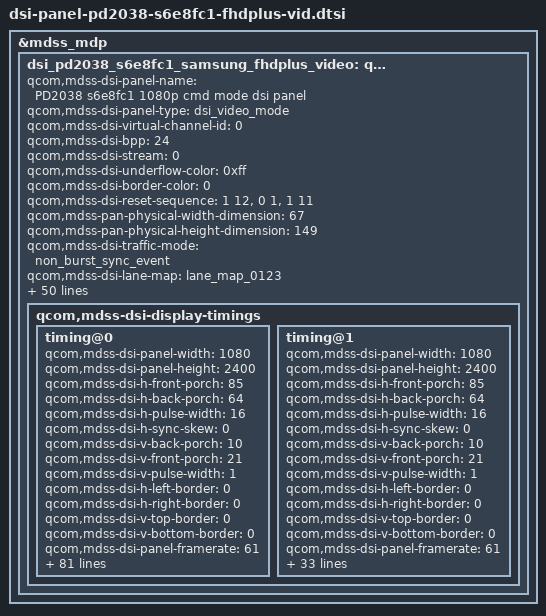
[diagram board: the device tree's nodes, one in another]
/* Copyright (c) 2019, The Linux Foundation. All rights reserved.
 *
 * This program is free software; you can redistribute it and/or modify
 * it under the terms of the GNU General Public License version 2 and
 * only version 2 as published by the Free Software Foundation.
 *
 * This program is distributed in the hope that it will be useful,
 * but WITHOUT ANY WARRANTY; without even the implied warranty of
 * MERCHANTABILITY or FITNESS FOR A PARTICULAR PURPOSE.  See the
 * GNU General Public License for more details.
 */

&mdss_mdp {
	dsi_pd2038_s6e8fc1_samsung_fhdplus_video: qcom,PD2038_mdss_dsi_s6e8fc1_fhdplus_cmd {
		qcom,mdss-dsi-panel-name = "PD2038 s6e8fc1 1080p cmd mode dsi panel";
		qcom,mdss-dsi-panel-type = "dsi_video_mode";
		qcom,mdss-dsi-virtual-channel-id = <0>;
		qcom,mdss-dsi-bpp = <24>;
		qcom,mdss-dsi-stream = <0>;
		qcom,mdss-dsi-underflow-color = <0xff>;
		qcom,mdss-dsi-border-color = <0>;
		qcom,mdss-dsi-reset-sequence = <1 12>, <0 1>, <1 11>;
		qcom,mdss-pan-physical-width-dimension = <67>;
		qcom,mdss-pan-physical-height-dimension = <149>;
		qcom,mdss-dsi-traffic-mode = "non_burst_sync_event";
		qcom,mdss-dsi-lane-map = "lane_map_0123";
		qcom,mdss-dsi-bllp-eof-power-mode;
		qcom,mdss-dsi-bllp-power-mode;
		qcom,mdss-dsi-lane-0-state;
		qcom,mdss-dsi-lane-1-state;
		qcom,mdss-dsi-lane-2-state;
		qcom,mdss-dsi-lane-3-state;
		qcom,mdss-dsi-dma-trigger = "trigger_sw";
		qcom,mdss-dsi-mdp-trigger = "none";
		qcom,mdss-dsi-lp11-init;
		qcom,mdss-dsi-panel-id = <0x20>;
		qcom,mdss-dsi-project-name = "pd2038";
		qcom,vivo-dsi-panel-type = "oled";
		qcom,mdss-dsi-te-pin-select = <1>;
		qcom,mdss-dsi-wr-mem-start = <0x2c>;
		qcom,mdss-dsi-wr-mem-continue = <0x3c>;
		qcom,mdss-dsi-te-dcs-command = <1>;
		qcom,mdss-dsi-te-check-enable;
		qcom,mdss-dsi-te-using-te-pin;
		qcom,ud-fingerprint-support;
		qcom,dc-dimming-support;
		qcom,dc-dimming-wait-te-count = <0>;
		qcom,aod-power-ddic;
		qcom,smart-aod-support;
		qcom,dc-dimming-close-dither-threshold = <130>;
		/* <area_id depth_bit x_start ystart width height> */
		qcom,smart-aod-fingerprint-area = <5 4 445 2075 192 190>;
		qcom,mdss-dsi-panel-mode-switch;
		qcom,mdss-panel-sre;
		qcom,mdss-dsi-aod-bl-level = <350>;
		//qcom,esd-check-enabled;
		qcom,mdss-dsi-panel-status-check-mode = "reg_read";
		qcom,mdss-dsi-panel-status-command = [06 01 00 01 00 00 01 0a];
		qcom,mdss-dsi-panel-status-command-state = "dsi_lp_mode";
		qcom,mdss-dsi-panel-status-value = <0x9F>;
		qcom,mdss-dsi-panel-on-check-value = <0x9F>;
		qcom,mdss-dsi-panel-status-read-length = <1>;
		qcom,mdss-dsi-t-clk-post = <0x0F>;

		qcom,mdss-dsi-t-clk-pre = <0x3A>;

		qcom,panel-supply-entries = <&dsi_panel_pwr_supply_no_labibb>;
		qcom,mdss-dsi-bl-pmic-control-type = "bl_ctrl_dcs";
		qcom,mdss-dsi-bl-min-level = <1>;
		qcom,mdss-dsi-bl-max-level = <2047>;
		qcom,mdss-brightness-max-level = <2047>;
		qcom,platform-en-gpio = <&tlmm 101 0>;
		qcom,platform-te-gpio = <&tlmm 89 0>;
		qcom,platform-reset-gpio = <&tlmm 90 0>;


		qcom,mdss-dsi-display-timings {
			timing@0{
				qcom,mdss-dsi-panel-width = <1080>;
				qcom,mdss-dsi-panel-height = <2400>;
				qcom,mdss-dsi-h-front-porch = <85>;
				qcom,mdss-dsi-h-back-porch = <64>;
				qcom,mdss-dsi-h-pulse-width = <16>;
				qcom,mdss-dsi-h-sync-skew = <0>;
				qcom,mdss-dsi-v-back-porch = <10>;
				qcom,mdss-dsi-v-front-porch = <21>;
				qcom,mdss-dsi-v-pulse-width = <1>;
				qcom,mdss-dsi-h-left-border = <0>;
				qcom,mdss-dsi-h-right-border = <0>;
				qcom,mdss-dsi-v-top-border = <0>;
				qcom,mdss-dsi-v-bottom-border = <0>;
				qcom,mdss-dsi-panel-framerate = <61>;
				qcom,mdss-dsi-video-mode;

				qcom,mdss-dsi-panel-phy-timings =
				[26 20 0A 0B 08 02 04 a0
				 26 20 0A 0B 08 02 04 a0
				 26 20 0A 0B 08 02 04 a0
				 26 20 0A 0B 08 02 04 a0
				 26 21 0A 0B 08 02 04 a0]; /* clk lane */
				qcom,display-topology = <1 0 1>;
				qcom,default-topology-index = <0>;

				qcom,mdss-dsi-on-command = [
					/* Sleep Out */
					39 01 00 00 15 00 02 11 00
					/* OSC change 91.3M */
					39 00 00 00 00 00 03 FC 5A 5A
					39 00 00 00 00 00 16 DF 09 30 95 42 BF 05 00 27 20 2E 4F 7A 77 10 3D 73 00 FF 01 8B 08
					39 01 00 00 0B 00 03 FC A5 A5
					39 00 00 00 00 00 03 F0 5A 5A
					39 00 00 00 00 00 03 B0 15 C3
					39 00 00 00 00 00 02 C3 42
					39 00 00 00 00 00 03 B0 17 C3
					39 00 00 00 00 00 02 C3 51
					39 00 00 00 00 00 02 F7 03
					39 01 00 00 00 00 03 F0 A5 A5

					/* PCD off */
					39 00 00 00 00 00 03 F0 5A 5A
					39 00 00 00 00 00 02 EA 40
					39 01 00 00 00 00 03 F0 A5 A5
				];

				qcom,mdss-oled-display-on-command =
				[
					39 00 00 00 00 00 03 F0 5A 5A
					/* dimming setting */
					39 00 00 00 00 00 03 B0 06 B3
					39 00 00 00 00 00 02 B3 01
					/* ACL dimmming */
					39 00 00 00 00 00 03 B0 B1 B5
					39 00 00 00 00 00 02 B5 48
					39 01 00 00 00 00 03 F0 A5 A5
					39 00 00 00 00 00 02 53 20
					39 00 00 00 00 00 03 9F A5 A5
					39 00 00 00 00 00 02 13 00
					39 00 00 00 00 00 02 29 00
					39 01 00 00 00 00 03 9F 5A 5A
					/* seed crc */
					39 00 00 00 00 00 03 F0 5A 5A
					39 00 00 00 00 00 03 9F A5 A5
					39 00 00 00 00 00 03 B0 01 B1
					39 00 00 00 00 00 16 B1 FF 00 04 10 FF 00 07 07 FF 15 FF E2 FF 04 Ec FF F7 00 FF FF FF
					39 00 00 00 00 00 02 80 90
					39 00 00 00 00 00 03 B0 55 B1
					39 00 00 00 00 00 02 B1 80
					39 00 00 00 00 00 02 B1 00
					39 00 00 00 00 00 03 9F 5A 5A
					39 01 00 00 00 00 03 F0 A5 A5
				];

				/* samsung OLED CRC mode P3 */
				qcom,mdss-oled-seed-crc-on-command-p3 =
				[
					39 00 00 00 00 00 03 F0 5A 5A
					39 00 00 00 00 00 17 B1 00 FF 00 04 10 FF 00 07 07 FF 15 FF E2 FF 04 EC FF F7 00 FF FF FF
					39 01 00 00 00 00 03 F0 A5 A5
				];
				/* samsung OLED CRC mode SRGB*/
				qcom,mdss-oled-seed-crc-on-command-srgb =
				[
					39 00 00 00 00 00 03 F0 5A 5A
					39 00 00 00 00 00 17 B1 00 B8 05 05 48 E2 16 06 09 BA 5B FF E5 CF 11 CE F6 EE 1E FF FB E0
					39 01 00 00 00 00 03 F0 A5 A5
				];
				/* samsung OLED CRC mode off*/
				qcom,mdss-oled-seed-crc-off-command =
				[
					39 00 00 00 00 00 03 F0 5A 5A
					39 00 00 00 00 00 02 B1 01
					39 01 00 00 00 00 03 F0 A5 A5
				];

				/*seed crc compenstate default 550~2047*/
				qcom,mdss-oled-seed-crc-compensate-p3-level0 =
				[
					39 00 00 00 00 00 03 F0 5A 5A
					39 00 00 00 00 00 17 B1 00 FF 00 04 10 FF 00 07 07 FF 15 FF E2 FF 04 EC FF F7 00 FF FF FF
					39 01 00 00 00 00 03 F0 A5 A5
				];
				/*seed crc compenstate 100nit 250~550*/
				qcom,mdss-oled-seed-crc-compensate-p3-level1 =
				[
					39 00 00 00 00 00 03 F0 5A 5A
					39 00 00 00 00 00 17 B1 00 FF 00 03 09 FF 00 05 05 FF 0D FF D9 FF 03 E4 FF F9 00 FF FF FF
					39 01 00 00 00 00 03 F0 A5 A5
				];
				/*seed crc compenstate 20nit 50~250*/
				qcom,mdss-oled-seed-crc-compensate-p3-level2 =
				[
					39 00 00 00 00 00 03 F0 5A 5A
					39 00 00 00 00 00 17 B1 00 FF 00 00 09 FF 00 04 05 FF 0C FF D4 FF 03 E4 FF FB 00 FC FF FC
					39 01 00 00 00 00 03 F0 A5 A5
				];
				/*seed crc compenstate 3nit 4~50*/
				qcom,mdss-oled-seed-crc-compensate-p3-level3 =
				[
					39 00 00 00 00 00 03 F0 5A 5A
					39 00 00 00 00 00 17 B1 00 FF 00 00 04 FF 00 02 03 FF 05 FF D6 FF 01 E0 FF F5 00 FF FF FF
					39 01 00 00 00 00 03 F0 A5 A5
				];

				/*seed crc compenstate default 550~2047*/
				qcom,mdss-oled-seed-crc-compensate-srgb-level0 =
				[
					39 00 00 00 00 00 03 F0 5A 5A
					39 00 00 00 00 00 17 B1 00 B8 05 05 48 E2 16 06 09 BA 5B FF E5 CF 11 CE F6 EE 1E FF FB E0
					39 01 00 00 00 00 03 F0 A5 A5
				];
				/*seed crc compenstate 100nit 250~550*/
				qcom,mdss-oled-seed-crc-compensate-srgb-level1 =
				[
					39 00 00 00 00 00 03 F0 5A 5A
					39 00 00 00 00 00 17 B1 00 B8 04 04 3C E2 11 05 07 BA 4B FF DC CF 0C CB F6 F0 17 FF FB DA
					39 01 00 00 00 00 03 F0 A5 A5
				];
				/*seed crc compenstate 20nit 50~250*/
				qcom,mdss-oled-seed-crc-compensate-srgb-level2 =
				[
					39 00 00 00 00 00 03 F0 5A 5A
					39 00 00 00 00 00 17 B1 00 B8 03 03 39 E2 10 05 06 BA 48 FF D9 CF 0A CB F6 F1 15 FF FD D8
					39 01 00 00 00 00 03 F0 A5 A5
				];
				/*seed crc compenstate 3nit 4~50*/
				qcom,mdss-oled-seed-crc-compensate-srgb-level3 =
				[
					39 00 00 00 00 00 03 F0 5A 5A
					39 00 00 00 00 00 17 B1 00 B8 02 02 38 E2 0E 03 04 BA 45 FF DA CF 06 C4 F6 F1 15 FF F6 D4
					39 01 00 00 00 00 03 F0 A5 A5
				];

				/* samsung OLED HBM mode */
				qcom,mdss-oled-hbm-on-command-level1 =
				[
					39 00 00 00 00 00 02 53 E8
					39 01 00 00 00 00 03 51 01 7B
				];

				qcom,mdss-oled-hbm-on-command-level2 =
				[
					39 00 00 00 00 00 02 53 E8
					39 01 00 00 00 00 03 51 02 83
				];

				qcom,mdss-oled-hbm-off-command =
				[
					39 01 00 00 00 00 02 53 28
				];

				/*fod on sequence
				1.ELVSS DIM OFF & DLY OFF
				2.HBM MODE ON
				3.Wait 1-Frame
				4.PS OFF
				5.image data write
				*/

				qcom,mdss-oled-set-dimming-off-hbm-ud-on =
				[
					/* dimming off */
					39 00 00 00 00 00 02 53 20
					/* elvss dimming off */
					39 00 00 00 00 00 03 F0 5A 5A
					39 00 00 00 00 00 03 B0 05 B3
					39 00 00 00 00 00 02 B3 07
					39 00 00 00 00 00 03 F0 A5 A5
					/* DLY OFF */
					39 00 00 00 00 00 03 F0 5A 5A
					39 00 00 00 00 00 03 B0 01 B3
					39 00 00 00 00 00 02 B3 4B
					39 00 00 00 00 00 03 F0 A5 A5
					/* HBM MODE ON */
					39 00 00 00 00 00 02 53 E0
					39 01 00 00 00 00 03 51 03 29  /*600nit*/
				];

				qcom,mdss-oled-set-dimming-off-hbm-ud-on-sync =
				[
					/* dimming off */
					39 00 00 00 00 00 02 53 20
					/* elvss dimming off and wait vblank irq */
					39 00 00 00 00 00 03 F0 5A 5A
					39 00 00 00 00 00 03 B0 05 B3
					39 00 00 00 00 00 02 B3 07
					39 01 00 00 00 00 03 F0 A5 A5
					/* DLY OFF */
					39 00 00 00 00 00 03 F0 5A 5A
					39 00 00 00 00 00 03 B0 01 B3
					39 00 00 00 00 00 02 B3 4B
					39 00 00 00 00 00 03 F0 A5 A5
					/* HBM MODE ON */
					39 00 00 00 00 00 02 53 E0
					39 01 00 00 00 00 03 51 03 29  /*600nit*/
				];

				qcom,mdss-oled-set-hbm-ud-off-no-lastcommand =
				[
					/* HBM MODE OFF */
					39 00 00 00 00 00 02 53 20
				];

				/* elvss dim on*/
				qcom,mdss-oled-elvss-dim-on-command =
				[
					39 00 00 00 00 00 03 F0 5A 5A
					39 00 00 00 00 00 03 B0 05 B3
					39 00 00 00 00 00 02 B3 87
					39 01 00 00 00 00 03 F0 A5 A5
				];
				/* elvss dim off*/
				qcom,mdss-oled-elvss-dim-off-command =
				[
					39 00 00 00 00 00 03 F0 5A 5A
					39 00 00 00 00 00 03 B0 05 B3
					39 00 00 00 00 00 02 B3 07
					39 01 00 00 00 00 03 F0 A5 A5
				];
				/*fod out sequence:
				1.HBM MODE OFF
				2.PS ON(ignore)
				3.ELVSS DIM ON & DLY ON
				4.image data write
				*/
				qcom,mdss-oled-hbm-off-command-ud-fingerprint =
				[
					/* HBM MODE OFF */
					39 01 00 00 00 00 02 53 20
				];

				qcom,mdss-oled-acl-on-command-level1 =
				[
					39 01 00 00 00 00 02 55 01
				];

				qcom,mdss-oled-acl-on-command-level2 =
				[
					39 01 00 00 00 00 02 55 02
				];

				qcom,mdss-oled-acl-on-command-level3 =
				[
					39 01 00 00 00 00 02 55 03
				];

				qcom,mdss-oled-acl-off-command =
				[
					39 01 00 00 00 00 02 55 00
				];

				qcom,mdss-oled-dimming-speed =
				[
					39 00 00 00 00 00 03 F0 5A 5A
					39 00 00 00 00 00 03 B0 06 B3
					39 00 00 00 00 00 02 B3 28
					39 00 00 00 00 00 03 F0 A5 A5
					39 01 00 00 00 00 02 53 28
				];

				qcom,mdss-oled-dimming-speed-off =
				[
					39 01 00 00 00 00 02 53 20
				];

				qcom,video-to-cmd-mode-switch-commands = [

				];

				qcom,mdss-oled-aod-on-command =
				[
					39 00 00 00 00 00 03 9F A5 A5
					39 00 00 00 00 00 02 28 00
					39 01 00 00 00 00 03 9F 5A 5A
				];

				qcom,cmd-to-video-mode-post-switch-commands = [
					/*D-IC MIPI vid mode*/
					39 00 00 00 00 00 03 F0 5A 5A
					39 00 00 00 00 00 02 F2 0F   /*03:cmd; 0F video*/
					39 00 00 00 00 00 03 F0 A5 A5
					/*AOD Mode OFF*/
					39 00 00 00 00 00 02 53 20
					/*AOD AMP Setting off*/
					39 00 00 00 00 00 03 FC 5A 5A
					39 00 00 00 00 00 03 B0 05 FD
					39 00 00 00 00 00 02 FD 6F
					39 00 00 00 00 00 03 FC A5 A5
					/*display on*/
					39 00 00 00 00 00 03 9F A5 A5
					39 00 00 00 00 00 02 29 00
					39 01 00 00 00 00 03 9F 5A 5A
				];
				qcom,video-to-cmd-mode-switch-commands-state =
						"dsi_lp_mode";
				qcom,mdss-alpm-command-state = "dsi_hs_mode";
				qcom,mdss-dsi-pre-off-command = [
					39 00 00 00 00 00 03 9F A5 A5
					39 01 00 00 0B 00 02 28 00
					39 01 00 00 00 00 02 10 00
				];
				qcom,mdss-dsi-off-command = [
					39 01 00 00 99 00 03 9F 5A 5A
				];



				qcom,mdss-oled-seed-crc-compensate-command-state = "dsi_hs_mode";
				qcom,mdss-dsi-on-command-state = "dsi_lp_mode";
				qcom,mdss-dsi-pre-off-command-state = "dsi_lp_mode";
				qcom,mdss-dsi-off-command-state = "dsi_lp_mode";
				qcom,mdss-dsi-h-sync-pulse = <0>;
				qcom,mdss-default-command-state = "dsi_hs_mode";
			};
			timing@1{
				qcom,mdss-dsi-panel-width = <1080>;
				qcom,mdss-dsi-panel-height = <2400>;
				qcom,mdss-dsi-h-front-porch = <85>;
				qcom,mdss-dsi-h-back-porch = <64>;
				qcom,mdss-dsi-h-pulse-width = <16>;
				qcom,mdss-dsi-h-sync-skew = <0>;
				qcom,mdss-dsi-v-back-porch = <10>;
				qcom,mdss-dsi-v-front-porch = <21>;
				qcom,mdss-dsi-v-pulse-width = <1>;
				qcom,mdss-dsi-h-left-border = <0>;
				qcom,mdss-dsi-h-right-border = <0>;
				qcom,mdss-dsi-v-top-border = <0>;
				qcom,mdss-dsi-v-bottom-border = <0>;
				qcom,mdss-dsi-panel-framerate = <61>;
				qcom,mdss-dsi-panel-jitter = <0x4 0x1>;
				qcom,mdss-dsi-panel-clockrate = <1108189440>;
				qcom,mdss-dsi-cmd-mode;

				qcom,mdss-dsi-panel-phy-timings =
				[26 20 0A 0B 08 02 04 a0
				 26 20 0A 0B 08 02 04 a0
				 26 20 0A 0B 08 02 04 a0
				 26 20 0A 0B 08 02 04 a0
				 26 21 0A 0B 08 02 04 a0]; /* clk lane */
				qcom,display-topology = <1 0 1>;
				qcom,default-topology-index = <0>;

				qcom,mdss-dsi-on-command = [
					/* Sleep Out */
					39 01 00 00 15 00 02 11 00
					/* OSC change 91.3M */
					39 00 00 00 00 00 03 FC 5A 5A
					39 00 00 00 00 00 16 DF 09 30 95 42 BF 05 00 27 20 2E 4F 7A 77 10 3D 73 00 FF 01 8B 08
					39 01 00 00 0B 00 03 FC A5 A5
					39 00 00 00 00 00 03 F0 5A 5A
					39 00 00 00 00 00 03 B0 15 C3
					39 00 00 00 00 00 02 C3 42
					39 00 00 00 00 00 03 B0 17 C3
					39 00 00 00 00 00 02 C3 51
					39 00 00 00 00 00 02 F7 03
					39 01 00 00 00 00 03 F0 A5 A5

					/* PCD off */
					39 01 00 00 00 00 03 F0 5A 5A
					39 01 00 00 00 00 02 EA 40
					39 01 00 00 64 00 03 F0 A5 A5
					/* delay 100ms */
					/* D-IC MIPI cmd mode */
					39 01 00 00 00 00 03 F0 5A 5A
					39 01 00 00 00 00 02 F2 03
					39 01 00 00 22 00 03 F0 A5 A5
					/* TE on */
					39 01 00 00 00 00 03 9F A5 A5
					39 01 00 00 00 00 02 35 00
					39 01 00 00 00 00 03 9F 5A 5A
				];

				/* samsung OLED AOD mode, defaut mode  HLPM high brightness */
				qcom,mdss-oled-aod-on-command =
				[
					/* AOD AMP Setting on */
					39 01 00 00 00 00 03 FC 5A 5A
					39 01 00 00 00 00 03 B0 06 FD
					39 01 00 00 00 00 02 FD 85
					39 01 00 00 00 00 03 FC A5 A5
					39 01 00 00 00 00 03 F0 5A 5A
					/* VLOUT3 change */
					39 01 00 00 00 00 03 B0 0B F4
					39 01 00 00 00 00 02 F4 8C
					/* V1 GAMMA */
					39 01 00 00 00 00 02 B0 B3
					39 01 00 00 00 00 05 B8 04 81 20 67
					/* AOD Mode on setting 50nit */
					39 01 00 00 00 00 02 B0 41
					39 01 00 00 00 00 02 B9 A0
					39 01 00 00 00 00 02 53 22
					39 01 00 00 00 00 03 F0 A5 A5
				];

				qcom,mdss-oled-aod-off-command =
				[
					39 00 00 00 00 00 03 9F A5 A5
					39 00 00 00 00 00 02 28 00
					39 01 00 00 00 00 03 9F 5A 5A
				];

				qcom,mdss-oled-aod-on-display-on-command = [
					39 00 00 00 00 00 03 9F A5 A5
					39 00 00 00 00 00 02 29 00
					39 01 00 00 00 00 03 9F 5A 5A
				];

				qcom,cmd-to-video-mode-switch-commands = [

				];

				qcom,video-to-cmd-mode-post-switch-commands = [
					/* D-IC MIPI cmd mode */
					39 01 00 00 00 00 03 F0 5A 5A
					39 01 00 00 00 00 02 F2 03
					39 01 00 00 22 00 03 F0 A5 A5
					/* TE ON */
					39 01 00 00 00 00 03 9F A5 A5
					39 01 00 00 00 00 02 35 00
					39 01 00 00 00 00 03 9F 5A 5A
					/* AOD AMP Setting on */
					39 01 00 00 00 00 03 FC 5A 5A
					39 01 00 00 00 00 03 B0 06 FD
					39 01 00 00 00 00 02 FD 85
					39 01 00 00 00 00 03 FC A5 A5
					39 01 00 00 00 00 03 F0 5A 5A
					/* VLOUT3 change */
					39 01 00 00 00 00 03 B0 0B F4
					39 01 00 00 00 00 02 F4 8C
					/* V1 GAMMA */
					39 01 00 00 00 00 02 B0 B3
					39 01 00 00 00 00 05 B8 04 81 20 67
					/* AOD Mode on setting 50nit */
					39 01 00 00 00 00 02 B0 41
					39 01 00 00 00 00 02 B9 A0
					39 01 00 00 00 00 02 53 22
					39 01 00 00 22 00 03 F0 A5 A5
				];

				qcom,cmd-to-video-mode-switch-commands-state =
						"dsi_lp_mode";
				qcom,cmd-to-video-mode-post-switch-commands-state =
						"dsi_lp_mode";
				qcom,video-to-cmd-mode-post-switch-commands-state =
						"dsi_lp_mode";
				qcom,mdss-alpm-command-state = "dsi_lp_mode";
				qcom,mdss-dsi-pre-off-command = [
					/*display off*/
					39 01 00 00 00 00 03 9F A5 A5
					39 01 00 00 0B 00 02 28 00
					39 01 00 00 00 00 03 9F 5A 5A
					/*D-IC MIPI vid mode*/
					39 01 00 00 00 00 03 F0 5A 5A
					39 01 00 00 22 00 02 F2 0F   /*03:cmd; 0F video*/
					39 01 00 00 00 00 03 F0 A5 A5
					/*AOD Mode OFF*/
					39 01 00 00 00 00 02 53 20
					/*AOD AMP Setting off*/
					39 01 00 00 00 00 03 FC 5A 5A
					39 01 00 00 00 00 03 B0 06 FD
					39 01 00 00 00 00 02 FD 05
					39 01 00 00 00 00 03 FC A5 A5
					/*sleep in*/
					39 01 00 00 00 00 03 9F A5 A5
					39 01 00 00 00 00 02 10 00
					39 01 00 00 99 00 03 9F 5A 5A
				];
				qcom,mdss-oled-display-on-command =
				[
					/*display off*/
					39 01 00 00 00 00 03 9F A5 A5
					39 01 00 00 00 00 02 28 00
					39 01 00 00 22 00 03 9F 5A 5A
					/*D-IC MIPI vid mode*/
					39 01 00 00 00 00 03 F0 5A 5A
					39 01 00 00 22 00 02 F2 0F   /*03:cmd; 0F video*/
					39 01 00 00 00 00 03 F0 A5 A5
					/*AOD Mode OFF*/
					39 01 00 00 00 00 02 53 20
					/*AOD AMP Setting off*/
					39 01 00 00 00 00 03 FC 5A 5A
					39 01 00 00 00 00 03 B0 06 FD
					39 01 00 00 00 00 02 FD 05
					39 01 00 00 00 00 03 FC A5 A5
					/*display on*/
					39 01 00 00 00 00 03 9F A5 A5
					39 01 00 00 00 00 02 29 00
					39 01 00 00 00 00 03 9F 5A 5A
				];
				qcom,mdss-dsi-on-command-state = "dsi_lp_mode";
				qcom,mdss-dsi-pre-off-command-state = "dsi_lp_mode";
				qcom,mdss-dsi-h-sync-pulse = <0>;
			};
		};
	};
};
